# R7FA4L1BD register map
Vendor: Renesas Electronics Corporation; Series: RA4; File version: 0.90.02
CPU: CM33 r0p4, little endian, MPU, FPU, VTOR, 4 interrupt priority bits, 96 interrupts
Registers are 32-bit, read-write, reset 0x0 unless marked. A register's access mark holds for its fields unless they carry their own. Offsets are from the block's base; [hi:lo] are bit positions; <NAME> marks a mode.

## DOC_B — Data Operation Circuit
Base 0x40109000
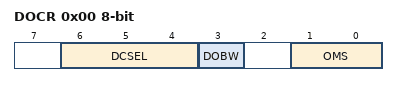
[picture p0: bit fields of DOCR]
0x00 DOCR 8-bit — DOC Control Register
  [6:4] DCSEL — Detection Condition Select
    0=Mismatch (DODSR0 ≠ DODIR); 1=Match (DODSR0 = DODIR); 2=Lower (DODSR0 > DODIR); 3=Upper (DODSR0 < DODIR); 4=Inside window (DODSR0 < DODIR < DODSR1); 5=Outside window (DODIR < DODSR0, DODSR1 < DODIR); other=Others (Setting prohibited)
  [3] DOBW — Data Operation Bit Width Select
    0=16-bit; 1=32-bit
  [1:0] OMS — Operating Mode Select
    0=Data comparison mode; 1=Data addition mode; 2=Data subtraction mode; 3=Setting prohibited
0x04 DOSR 8-bit ro — DOC Flag Status Register
  [0] DOPCF — Data Operation Circuit Flag
0x08 DOSCR 8-bit wo — DOC Flag Status Clear Register
  [0] DOPCFCL — DOPCF Clear
    0=Maintains the DOPCF flag state; 1=Clears the DOPCF flag
0x0C DODIR — DOC Data Input Register
0x10 DODSR0 — DOC Data Setting Register 0
0x14 DODSR1 — DOC Data Setting Register 1

## ECCMB
Base 0x4012F000
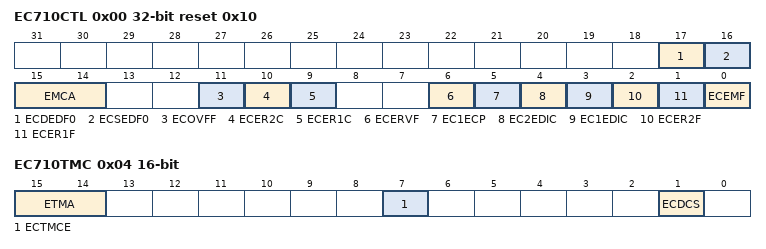
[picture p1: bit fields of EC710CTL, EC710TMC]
0x00 EC710CTL reset 0x10 — ECC Control Register
  [17] ECDEDF0 ro — 2-bit ECC Error Address Detection Flag
    0=2-bit error has not occurred after reset or clearing ECER2F bit; 1=2-bit error has occurred and the address was captured
  [16] ECSEDF0 ro — 1-bit ECC Error Address Detection Flag
    0=1-bit error has not occurred after reset or clearing ECER1F bit; 1=1-bit error has occurred and the address was captured
  [15:14] EMCA — ECC Error Detection Enable Access Control
    1=Can write ECC Error Detection Control (ECERVF) bit; other=Others (Cannot write ECERVF bit)
  [11] ECOVFF ro — ECC Overflow Detection Flag
    0=No clear flag; 1=Clear flag
  [10] ECER2C — 2-bit ECC Error Detection Flag Clear
    0=No clear flag; 1=Clear 2-bit ECC error detection flag
  [9] ECER1C — Accumulating ECC Error Detection and Correction Flag Clear
    0=No clear flag; 1=Clear accumulating ECC error detection and correction flag
  [6] ECERVF — ECC Error Detection Enable
    0=Disable error detection; 1=Enable error detection
  [5] EC1ECP — 1-bit ECC Error Correction Permission
    0=Enable error correction at 1-bit error detection; 1=Disable error correction at 1-bit error detection
  [4] EC2EDIC — 2-bit ECC Error Detection Interrupt Control
    0=Disable 2-bit error detection interrupt request; 1=Enable 2-bit error detection interrupt request
  [3] EC1EDIC — 1-bit ECC Error Detection Interrupt Control
    0=Disable 1-bit error detection interrupt request; 1=Enable 1-bit error detection interrupt request
  [2] ECER2F ro — 2-bit ECC Error Detection Flag
    0=After clearing this bit, 2-bit error has not detected; 1=2-bit error has detected
  [1] ECER1F ro — 1-bit ECC Error Detection and Correction Flag
    0=After clearing this bit, 1-bit error correction has not detected and corrected; 1=1-bit error has detected and corrected
  [0] ECEMF ro — ECC Error Message Flag
    0=There is no bit error in the present RAM output data; 1=There is a bit error in the present RAM output data
0x04 EC710TMC 16-bit — ECC Test Mode Control Register
  [15:14] ETMA — ECC Test Mode Bit Access Control
  [7] ECTMCE — ECC Test Mode Control Enable
    0=The access to test mode register and bit is disabled; 1=The access to test mode register and bit is enabled
  [1] ECDCS — ECC Decode Input Select
    0=Input lower 32 bits of RAM output data to data area of decode circuit; 1=Input ECEDB31-0 in EC710TED register to data area of decode circuit
0x0C EC710TED — ECC Test Substitute Data Register
  [31:0] ECEDB — ECC Test Substitute Data
0x10 EC710EAD0 ro — ECC Error Address Register
  [9:0] ECEAD — ECC Error Address
